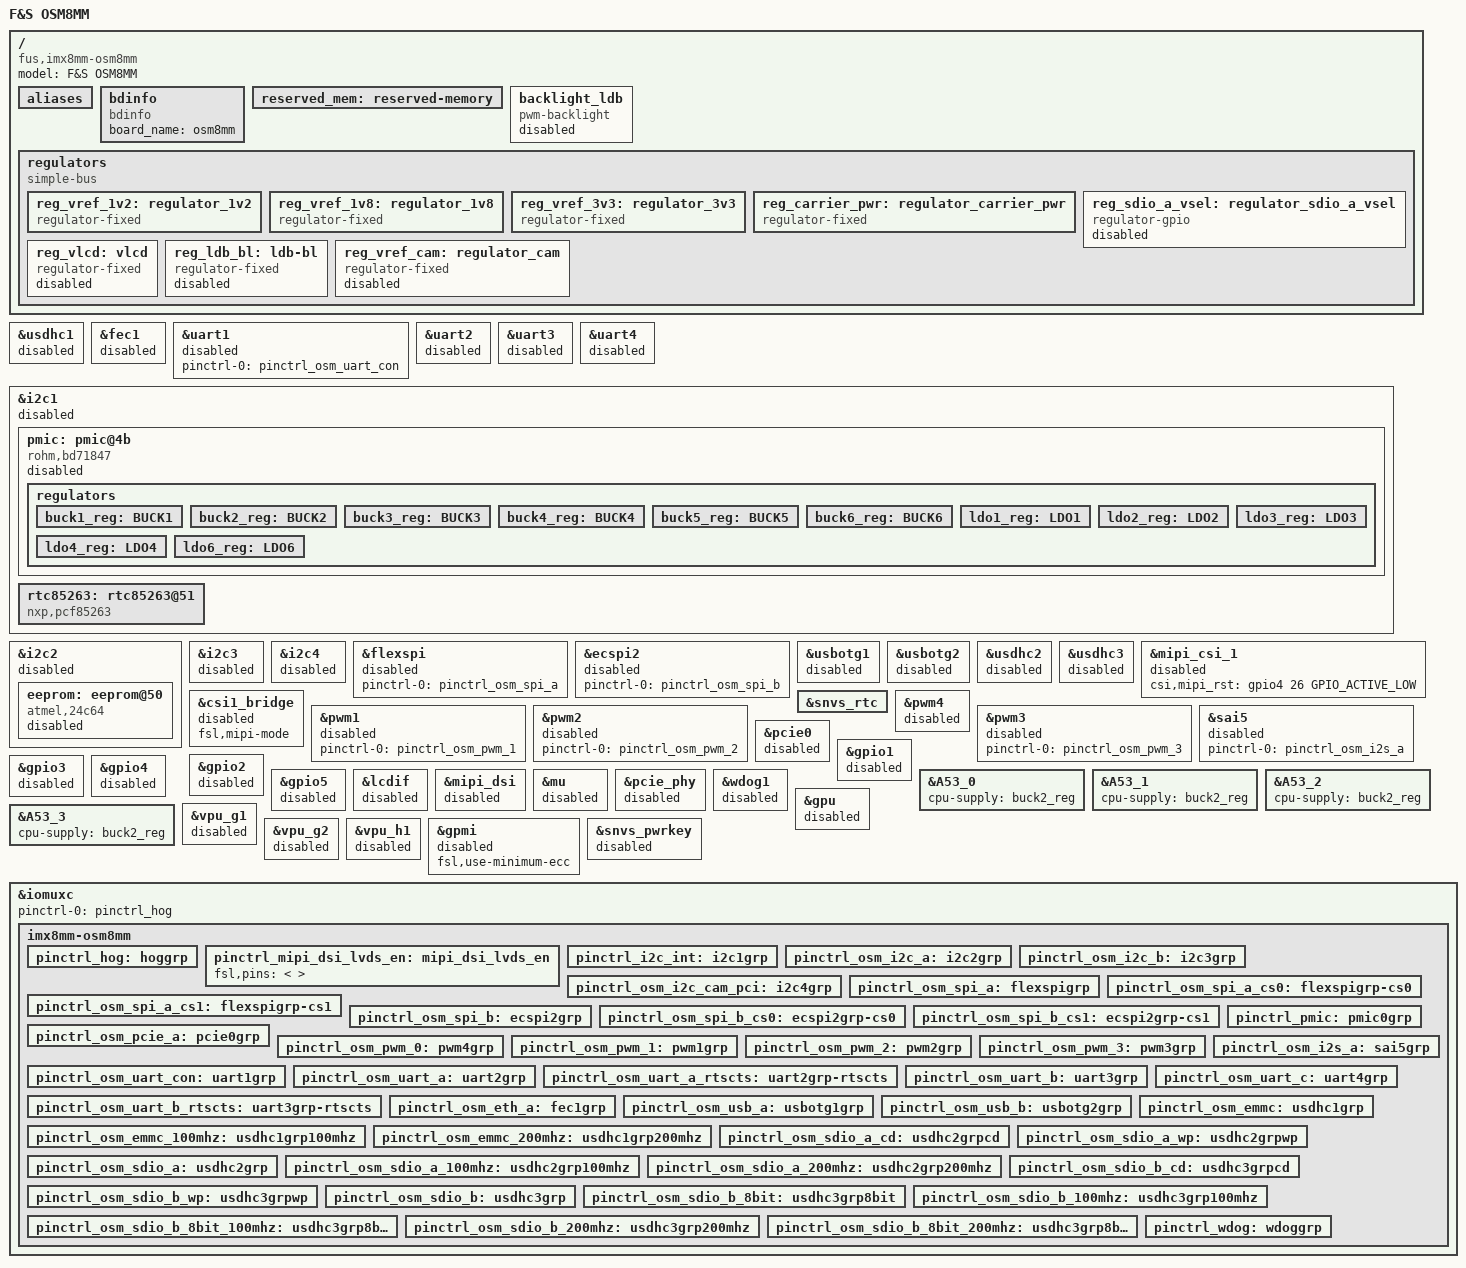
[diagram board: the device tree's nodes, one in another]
/*
 * Copyright (C) 2024 F&S Elektronik Systeme GmbH
 *
 * This program is free software; you can redistribute it and/or modify
 * it under the terms of the GNU General Public License version 2 as
 * published by the Free Software Foundation.
 */

#include <dt-bindings/pwm/pwm.h>
#include <dt-bindings/rtc/nxp,pcf85263.h>
#include <dt-bindings/usb/pd.h>
#include <dt-bindings/phy/phy-imx8-pcie.h>

/* SOC-nodes to OSM-nodes */
osm_emmc: &usdhc1 {};

osm_eth_a: &fec1 {};
osm_uart_con: &uart1 {};
osm_uart_a: &uart2 {};
osm_uart_b: &uart3 {};
osm_uart_c: &uart4 {};
i2c_int: &i2c1 {};
osm_i2c_a: &i2c2 {};
osm_i2c_b: &i2c3 {};
osm_i2c_cam_pci: &i2c4 {};
osm_spi_a: &flexspi {};
osm_spi_b: &ecspi2 {};
osm_usb_a: &usbotg1 {};
osm_usb_b: &usbotg2 {};
osm_sdio_a: &usdhc2 {};
osm_sdio_b: &usdhc3 {};
osm_csi: &mipi_csi_1 {};
osm_csi_bridge: &csi1_bridge {};
rtc_soc: &snvs_rtc {};
osm_pwm_0: &pwm4 {};
osm_pwm_1: &pwm1 {};
osm_pwm_2: &pwm2 {};
osm_pwm_3: &pwm3 {};
osm_i2s_a: &sai5 {};
osm_pcie_a: &pcie0 {};

/ {
	model = "F&S OSM8MM";
	compatible = "fus,imx8mm-osm8mm", "fsl,imx8mm";

	aliases {
		/* Alias for GPMI node. Dont change it
		 * because it used by the bootloader */
		nand = &gpmi;
		emmc = &osm_emmc;

		ethernet0 = &osm_eth_a;
		serial0 = &osm_uart_con;
		serial1 = &osm_uart_a;
		serial2 = &osm_uart_b;
		serial3 = &osm_uart_c;
		i2c0 = &i2c_int;
		i2c1 = &osm_i2c_a;
		i2c2 = &osm_i2c_b;
		i2c3 = &osm_i2c_cam_pci;
		spi0 = &osm_spi_a;
		spi1 = &osm_spi_b;
		usb0 = &osm_usb_a;
		usb1 = &osm_usb_b;
		mmc1 = &osm_sdio_a;
		mmc2 = &osm_sdio_b;
		csi0 = &osm_csi;
		rtc0 = &rtc85263;
		rtc1 = &rtc_soc;
		pwm0 = &osm_pwm_0;
		pwm1 = &osm_pwm_1;
		pwm2 = &osm_pwm_2;
		pwm3 = &osm_pwm_3;
	};

	/* -------------------- BOARD INFO -------------------- */
	bdinfo: bdinfo {
		compatible = "bdinfo";
		board_name = "osm8mm";
	};

	reserved_mem: reserved-memory {
		#address-cells = <2>;
		#size-cells = <2>;
		ranges;
	};

	/* M4/remoteproc reserved-memory + cm4 node live in the board dts,
	 * under its own SUPPORT_M4 guard, not here. */

	backlight_ldb: backlight_ldb {
		compatible = "pwm-backlight";
		#pwm-cells = <3>;
		pwms = <&osm_pwm_0 0 3000000 PWM_POLARITY_INVERTED>;
		power-supply = <&reg_ldb_bl>;
		brightness-levels = <0 1 5 10 18 28 41 56
				     73 92 113 137 163 192 222 255>;
		default-brightness-level = <14>;
		fb-names = "imx-drmdrmfb";
		status = "disabled";
	};

	regulators {
		compatible = "simple-bus";
		#address-cells = <1>;
		#size-cells = <0>;

		/* necessary for lcdif-tc35874-j070wvtc0211 */
		reg_vref_1v2: regulator_1v2 {
			compatible = "regulator-fixed";
			regulator-name = "vref-1V2";
			regulator-min-microvolt = <1200000>;
			regulator-max-microvolt = <1200000>;
			regulator-always-on;
		};

		reg_vref_1v8: regulator_1v8 {
			compatible = "regulator-fixed";
			regulator-name = "vref-1V8";
			regulator-min-microvolt = <1800000>;
			regulator-max-microvolt = <1800000>;
			regulator-always-on;
		};

		reg_vref_3v3: regulator_3v3 {
			compatible = "regulator-fixed";
			regulator-name = "vref-3V3";
			regulator-min-microvolt = <3300000>;
			regulator-max-microvolt = <3300000>;
			regulator-always-on;
		};

		reg_carrier_pwr: regulator_carrier_pwr {
			compatible = "regulator-fixed";
			regulator-name = "CARRIER_PWR";
			gpio = <&gpio4 27 GPIO_ACTIVE_HIGH>;
			regulator-min-microvolt = <3300000>;
			regulator-max-microvolt = <3300000>;
			regulator-boot-on;
			regulator-always-on;
			enable-active-high;
			startup-delay-us = <1000>;
			off-on-delay-us = <12000>;
		};

		/omit-if-no-ref/
		reg_sdio_a_vsel: regulator_sdio_a_vsel {
			compatible = "regulator-gpio";
			regulator-name = "SDIO_A_VSEL";
			gpios = <&gpio1 3 GPIO_ACTIVE_HIGH>;
			regulator-min-microvolt = <1800000>;
			regulator-max-microvolt = <3300000>;
			regulator-type = "voltage";
			regulator-boot-on;
			regulator-always-on;
			enable-active-high;
			states = <1800000 0x1 3300000 0x0>;
			status = "disabled";
		};

		/* LCD power on voltage */
		/omit-if-no-ref/
		reg_vlcd: vlcd {
			compatible = "regulator-fixed";
			regulator-name = "VLCD";
			gpio = <&gpio5 1 GPIO_ACTIVE_HIGH>;
			regulator-min-microvolt = <3300000>;
			regulator-max-microvolt = <3300000>;
			enable-active-high;
			startup-delay-us = <10000>;
			status = "disabled";
		};

		/omit-if-no-ref/
		reg_ldb_bl: ldb-bl {
			compatible = "regulator-fixed";
			regulator-name = "ldb-bl";
			gpio = <&gpio5 0 GPIO_ACTIVE_HIGH>;
			regulator-min-microvolt = <3300000>;
			regulator-max-microvolt = <3300000>;
			enable-active-high;
			status = "disabled";
		};

		/omit-if-no-ref/
		reg_vref_cam: regulator_cam {
			compatible = "regulator-fixed";
			regulator-name = "CAM_ENA";
			gpio = <&gpio4 25 GPIO_ACTIVE_HIGH>;
			regulator-min-microvolt = <1800000>;
			regulator-max-microvolt = <1800000>;
			enable-active-high;
			status = "disabled";
		};
	};

	/* M4/remoteproc rpmsg-audio example intentionally left out - was
	 * already dead (#if 0) in the original file. */
};

/* GPIO declarations */
&gpio1 {
	gpio-line-names =
	/* 0 */   "GPIO_A_0", "GPIO_A_1", "PMIC_WDOG", "SD_A_VSEL",
	/* 4 */   "GPIO_A_2", "GPIO_A_3", "GPIO_A_4", "GPIO_A_5",
	/* 8 */   "GPIO_B_0", "GPIO_B_1", "GPIO_B_2", "GPIO_B_3",
	/* 12 */  "USB_A_EN", "USB_A_OC", "USB_B_EN", "USB_B_OC",
	/* 16 */  "ETH_MDC", "ETH_MDIO", "ETH_A_(S)(R)(G)MII_TXD3", "ETH_A_(S)(R)(G)MII_TXD2",
	/* 20 */  "ETH_A_(S)(R)(G)MII_TXD1", "ETH_A_(S)(R)(G)MII_TXD0", "ETH_A_(R)(G)MII_TX_EN(_ER)", "ETH_A_(R)(G)MII_TX_CLK",
	/* 24 */  "ETH_A_(R)(G)MII_RX_DV(_ER)", "ETH_A_(R)(G)MII_RX_CLK", "ETH_A_(S)(R)(G)MII_RXD0", "ETH_A_(S)(R)(G)MII_RXD1",
	/* 28 */  "ETH_A_(R)(G)MII_RXD2", "ETH_A_(R)(G)MII_RXD3", "", "";
	status = "disabled";
};

&gpio2 {
	gpio-line-names =
	/* 0 */   "SD_eMMC_CLK", "SD_eMMC_CMD", "SD_eMMC_D0", "SD_eMMC_D1",
	/* 4 */   "SD_eMMC_D2", "SD_eMMC_D3", "SD_eMMC_D4", "SD_eMMC_D5",
	/* 8 */   "SD_eMMC_D6", "SD_eMMC_D7", "SD_eMMC_RST", "SD_eMMC_DS",
	/* 12 */  "SDIO_A_CD", "SDIO_A_CLK", "SDIO_A_CMD", "SDIO_A_D0",
	/* 16 */  "SDIO_A_D1", "SDIO_A_D2", "SDIO_A_D3", "SDIO_A_PWR_EN",
	/* 20 */  "SDIO_A_WP", "", "", "",
	/* 24 */  "", "", "", "",
	/* 28 */  "", "", "", "";
	status = "disabled";
};

&gpio3 {
	gpio-line-names =
	/* 0 */   "SPI_A_SCK", "SPI_A_CS0", "SPI_A_CS1", "SDIO_B_D5",
	/* 4 */   "SDIO_B_D6", "SDIO_B_D7", "SPI_A_IO0", "SPI_A_IO1",
	/* 8 */   "SPI_A_IO2", "SPI_A_IO3", "SDIO_B_D0", "SDIO_B_D1",
	/* 12 */  "SDIO_B_D2", "SDIO_B_D3", "", "SDIO_B_D4",
	/* 16 */  "SDIO_B_PWR_EN", "SDIO_B_CLK", "SDIO_B_CMD", "PCIe_PERST",
	/* 20 */  "PCIe_WAKE", "I2S_A_DATA_IN", "I2S_A_LRCLK", "I2S_A_BITCLK",
	/* 24 */  "I2S_A_DATA_OUT", "I2S_MCLK", "", "",
	/* 28 */  "", "", "", "";
	status = "disabled";
};

&gpio4 {
	gpio-line-names =
	/* 0 */   "", "", "", "GPIO_C_3",
	/* 4 */   "GPIO_C_2", "GPIO_C_1", "GPIO_C_0", "GPIO_B_7",
	/* 8 */   "GPIO_B_6", "GPIO_B_5", "", "",
	/* 12 */  "", "", "", "",
	/* 16 */  "", "", "", "",
	/* 20 */  "", "DSI_TE", "SDIO_B_CD", "SDIO_B_WP",
	/* 24 */  "PMIC_IRQ", "CAM_EN", "CAM_RST", "CARRIER_PWR_EN",
	/* 28 */  "PCIe_CLKREQ", "UART_A_RTS", "UART_A_CTS", "PCIe_SM_ALERT";
	status = "disabled";
};

&gpio5 {
	gpio-line-names =
	/* 0 */   "DISP_BL_EN", "DISP_VDD_EN", "DISP_BL_PWM", "PWM_3",
	/* 4 */   "PWM_2", "PWM_1", "SPI_B_CS1", "GPIO_B_4",
	/* 8 */   "UART_B_RTS", "UART_B_CTS", "SPI_B_SCK", "SPI_B_SDO",
	/* 12 */  "SPI_B_SDI", "SPI_B_CS0", "I2C_INT_SCL", "I2C_INT_SDA",
	/* 16 */  "I2C_A_SCL", "I2C_A_SDA", "I2C_B_SCL", "I2C_B_SDA",
	/* 20 */  "I2C_CAM_PCI_SCL", "I2C_CAM_PCI_SDA", "UART_CON_RX", "UART_CON_TX",
	/* 24 */  "UART_A_RX", "UART_A_TX", "UART_B_RX", "UART_B_TX",
	/* 28 */  "UART_C_RX", "UART_C_TX", "", "";
	status = "disabled";
};

/* OSM8MM_I2C_INT */
&i2c_int {
	clock-frequency = <100000>;
	pinctrl-names = "default";
	pinctrl-0 = <&pinctrl_i2c_int>;
	status = "disabled";

	/* PMIC */
	pmic: pmic@4b {
		compatible = "rohm,bd71847";
		reg = <0x4b>;
		pinctrl-names = "default";
		pinctrl-0 = <&pinctrl_pmic>;
		interrupt-parent = <&gpio4>;
		interrupts = <24 GPIO_ACTIVE_LOW>;
		rohm,reset-snvs-powered;

		#clock-cells = <0>;
		clocks = <&osc_32k 0>;
		clock-output-names = "clk-32k-out";
		status = "disabled";

		regulators {
			buck1_reg: BUCK1 {
				regulator-name = "BUCK1";
				regulator-min-microvolt = <700000>;
				regulator-max-microvolt = <1300000>;
				regulator-boot-on;
				regulator-always-on;
				regulator-ramp-delay = <1250>;
				rohm,dvs-run-voltage = <850000>;
				rohm,dvs-suspend-voltage = <750000>;
			};

			buck2_reg: BUCK2 {
				regulator-name = "BUCK2";
				regulator-min-microvolt = <700000>;
				regulator-max-microvolt = <1300000>;
				regulator-boot-on;
				regulator-always-on;
				regulator-ramp-delay = <1250>;
				rohm,dvs-run-voltage = <1000000>;
				rohm,dvs-idle-voltage = <900000>;
                rohm,dvs-suspend-voltage = <0>;
			};

			buck3_reg: BUCK3 {
				// BUCK5 in datasheet
				regulator-name = "BUCK3";
				regulator-min-microvolt = <700000>;
				regulator-max-microvolt = <1350000>;
				regulator-boot-on;
				regulator-always-on;
			};

			buck4_reg: BUCK4 {
				// BUCK6 in datasheet
				regulator-name = "BUCK4";
				regulator-min-microvolt = <3000000>;
				regulator-max-microvolt = <3300000>;
				regulator-boot-on;
				regulator-always-on;
			};

			buck5_reg: BUCK5 {
				// BUCK7 in datasheet
				regulator-name = "BUCK5";
				regulator-min-microvolt = <1605000>;
				regulator-max-microvolt = <1995000>;
				regulator-boot-on;
				regulator-always-on;
			};

			buck6_reg: BUCK6 {
				// BUCK8 in datasheet
				regulator-name = "BUCK6";
				regulator-min-microvolt = <800000>;
				regulator-max-microvolt = <1400000>;
				regulator-boot-on;
				regulator-always-on;
			};

			ldo1_reg: LDO1 {
				regulator-name = "LDO1";
				regulator-min-microvolt = <1600000>;
				regulator-max-microvolt = <1900000>;
				regulator-boot-on;
				regulator-always-on;
			};

			ldo2_reg: LDO2 {
				regulator-name = "LDO2";
				regulator-min-microvolt = <800000>;
				regulator-max-microvolt = <900000>;
				regulator-boot-on;
				regulator-always-on;
			};

			ldo3_reg: LDO3 {
				regulator-name = "LDO3";
				regulator-min-microvolt = <1800000>;
				regulator-max-microvolt = <3300000>;
				regulator-boot-on;
				regulator-always-on;
			};

			ldo4_reg: LDO4 {
				regulator-name = "LDO4";
				regulator-min-microvolt = <900000>;
				regulator-max-microvolt = <1800000>;
				regulator-boot-on;
				regulator-always-on;
			};

			ldo6_reg: LDO6 {
				regulator-name = "LDO6";
				regulator-min-microvolt = <900000>;
				regulator-max-microvolt = <1800000>;
				regulator-boot-on;
				regulator-always-on;
			};
		};
	};

	rtc85263: rtc85263@51 {
		compatible = "nxp,pcf85263";
		reg = <0x51>;
		clock-out = <PCF85263_CLK_OUT_32p768kHz>;

		quartz-load-capacitance = <PCF85263_QUARTZCAP_12p5pF>;
		quartz-drive-strength = <PCF85263_QUARTZDRIVE_LOW>;
	};
};

&osm_i2c_a {
	clock-frequency = <100000>;
	pinctrl-names = "default";
	pinctrl-0 = <&pinctrl_osm_i2c_a>;
	status = "disabled";

	/* EEPROM */
	eeprom: eeprom@50 {
		compatible = "atmel,24c64";
		reg = <0x50>;
		pagesize = <8>;
		vcc-supply = <&reg_vref_1v8>;
		status = "disabled";
	};
};

&osm_i2c_b {
	clock-frequency = <100000>;
	pinctrl-names = "default";
	pinctrl-0 = <&pinctrl_osm_i2c_b>;
	status = "disabled";
};

&osm_i2c_cam_pci {
	clock-frequency = <100000>;
	pinctrl-names = "default";
	pinctrl-0 = <&pinctrl_osm_i2c_cam_pci>;
	status = "disabled";
};

&lcdif {
	status = "disabled";
};

&mipi_dsi {
	status = "disabled";
};

&mu {
	status = "disabled";
};

&osm_pwm_0 {
	pinctrl-names = "default";
	pinctrl-0 = <&pinctrl_osm_pwm_0>;
	#pwm-cells = <3>;
	keep-power;
	status = "disabled";
};

&osm_pwm_1 {
	pinctrl-names = "default";
	pinctrl-0 = <&pinctrl_osm_pwm_1>;
	status = "disabled";
};

&osm_pwm_2 {
	pinctrl-names = "default";
	pinctrl-0 = <&pinctrl_osm_pwm_2>;
	status = "disabled";
};

&osm_pwm_3 {
	pinctrl-names = "default";
	pinctrl-0 = <&pinctrl_osm_pwm_3>;
	status = "disabled";
};

&osm_i2s_a {
	#sound-dai-cells = <0>;
	pinctrl-names = "default";
	pinctrl-0 = <&pinctrl_osm_i2s_a>;
	status = "disabled";
};

/* FSPI not implemented in the NXP FlexSPI driver on this SoC revision - the
 * ADP baseboard overlay deletes this node and replaces it with a
 * spi-gpio bitbang bus instead, see the board dts. */
&osm_spi_a {
	#address-cells = <1>;
	#size-cells = <0>;
	pinctrl-names = "default";
	pinctrl-0 = <&pinctrl_osm_spi_a>;
	status = "disabled";
};

&osm_spi_b {
	#address-cells = <1>;
	#size-cells = <0>;
	pinctrl-names = "default";
	pinctrl-0 = <&pinctrl_osm_spi_b>;
	status = "disabled";
};

&pcie_phy {
	fsl,refclk-pad-mode = <IMX8_PCIE_REFCLK_PAD_OUTPUT>;
	fsl,clkreq-unsupported;
	fsl,tx-deemph-gen1 = <0x2d>;
	fsl,tx-deemph-gen2 = <0xf>;
	status = "disabled";
};

&osm_pcie_a {
	pinctrl-names = "default";
	pinctrl-0 = <&pinctrl_osm_pcie_a>;
	reset-gpio = <&gpio3 19 GPIO_ACTIVE_LOW>;
	/* the wake pin of PCIe must be configured as normal
	 * wakeup source and it is not a specific driver issue
	 */
	//wake-gpio = <&gpio3 20 GPIO_ACTIVE_LOW>;
	assigned-clocks = <&clk IMX8MM_CLK_PCIE1_AUX>,
			  <&clk IMX8MM_CLK_PCIE1_CTRL>;
	assigned-clock-rates = <10000000>, <250000000>;
	assigned-clock-parents = <&clk IMX8MM_SYS_PLL2_50M>,
				 <&clk IMX8MM_SYS_PLL2_250M>;
	ext_osc = <0>;
	l1ss-disabled;
	status = "disabled";
};

&osm_uart_con { /* console */
	pinctrl-names = "default";
	pinctrl-0 = <&pinctrl_osm_uart_con>;
	status = "disabled";
};

&osm_uart_a {
	pinctrl-names = "default";
	pinctrl-0 = <&pinctrl_osm_uart_a>;
	assigned-clocks = <&clk IMX8MM_CLK_UART2>;
	assigned-clock-parents = <&clk IMX8MM_SYS_PLL1_80M>;
	status = "disabled";
};

&osm_uart_b {
	pinctrl-names = "default";
	pinctrl-0 = <&pinctrl_osm_uart_b>;
	assigned-clocks = <&clk IMX8MM_CLK_UART3>;
	assigned-clock-parents = <&clk IMX8MM_SYS_PLL1_80M>;
	status = "disabled";
};

&osm_uart_c {
	pinctrl-names = "default";
	pinctrl-0 = <&pinctrl_osm_uart_c>;
	assigned-clocks = <&clk IMX8MM_CLK_UART4>;
	assigned-clock-parents = <&clk IMX8MM_SYS_PLL1_80M>;
	status = "disabled";
};

&osm_eth_a {
	pinctrl-names = "default";
	pinctrl-0 = <&pinctrl_osm_eth_a>;
	fsl,magic-packet;
	status = "disabled";
};

&osm_usb_a {
	dr_mode = "otg";
	pinctrl-names = "default";
	pinctrl-0 = <&pinctrl_osm_usb_a>;
	picophy,pre-emp-curr-control = <3>;
	picophy,dc-vol-level-adjust = <7>;
	status = "disabled";
};

&osm_usb_b {
	dr_mode = "host";
	pinctrl-names = "default";
	pinctrl-0 = <&pinctrl_osm_usb_b>;
	power-active-high;
	picophy,pre-emp-curr-control = <3>;
	picophy,dc-vol-level-adjust = <7>;
	status = "disabled";
};

&osm_emmc {
	assigned-clocks = <&clk IMX8MM_CLK_USDHC1>;
	assigned-clock-rates = <400000000>;
	pinctrl-names = "default", "state_100mhz", "state_200mhz";
	pinctrl-0 = <&pinctrl_osm_emmc>;
	pinctrl-1 = <&pinctrl_osm_emmc_100mhz>;
	pinctrl-2 = <&pinctrl_osm_emmc_200mhz>;
	bus-width = <8>;
	non-removable;
	status = "disabled";
};

&osm_sdio_a {
	assigned-clocks = <&clk IMX8MM_CLK_USDHC2>;
	assigned-clock-rates = <200000000>;
	bus-width = <4>;
	voltage-ranges = <1800 3300>;
	vqmmc-supply = <&reg_sdio_a_vsel>;
	status = "disabled";
};

&osm_sdio_b {
	assigned-clocks = <&clk IMX8MM_CLK_USDHC3>;
	assigned-clock-rates = <200000000>;
	pinctrl-names = "default", "state_100mhz", "state_200mhz";
	pinctrl-0 = <&pinctrl_osm_sdio_b>;
	pinctrl-1 = <&pinctrl_osm_sdio_b_100mhz>;
	pinctrl-2 = <&pinctrl_osm_sdio_b_200mhz>;
	/* CD/WP/8-bit pinctrl groups and cd-gpios/wp-gpios/bus-width=<8> are
	 * added by the board dts, matching the actually populated pins */
	bus-width = <4>;
	vmmc-supply = <&reg_vref_3v3>;
	vqmmc-supply = <&reg_vref_3v3>;
	pm-ignore-notify;
	keep-power-in-suspend;
	status = "disabled";
};

/* camera-sensor-specific endpoint wiring lives in the board dts, only the
 * fixed CSI-receiver <-> bridge routing + reset line live here */
&osm_csi {
	#address-cells = <1>;
	#size-cells = <0>;
	csi,mipi_rst = <&gpio4 26 GPIO_ACTIVE_LOW>;
	status = "disabled";
};

&osm_csi_bridge {
	fsl,mipi-mode;
	status = "disabled";
};

&wdog1 {
	pinctrl-names = "default";
	pinctrl-0 = <&pinctrl_wdog>;
	fsl,ext-reset-output;
	status = "disabled";
};

&A53_0 {
	cpu-supply = <&buck2_reg>;
};
&A53_1 {
	cpu-supply = <&buck2_reg>;
};

&A53_2 {
	cpu-supply = <&buck2_reg>;
};

&A53_3 {
	cpu-supply = <&buck2_reg>;
};

&gpu {
	status = "disabled";
};

&vpu_g1 {
	status = "disabled";
};

&vpu_g2 {
	status = "disabled";
};

&vpu_h1 {
	status = "disabled";
};

&gpmi {
	fsl,use-minimum-ecc;
	status = "disabled";
};

&snvs_pwrkey {
	status = "disabled";
};

&iomuxc {
	pinctrl-names = "default";
	pinctrl-0 = <&pinctrl_hog>;

	imx8mm-osm8mm {
		/* Pin configs that don't belong anywhere else */
		pinctrl_hog: hoggrp {
			fsl,pins = <
				/* CARRIER_PWR_EN */
				MX8MM_IOMUXC_SAI2_MCLK_GPIO4_IO27	0x00004
				/* SD_A_VSEL */
				MX8MM_IOMUXC_GPIO1_IO03_GPIO1_IO3	0x00004

				/* GPIO_A */
				/* 0 */ MX8MM_IOMUXC_GPIO1_IO00_GPIO1_IO0	0x00004
				/* 1 */ MX8MM_IOMUXC_GPIO1_IO01_GPIO1_IO1	0x00004
				/* 2 */ MX8MM_IOMUXC_GPIO1_IO04_GPIO1_IO4	0x00004
				/* 3 */ MX8MM_IOMUXC_GPIO1_IO05_GPIO1_IO5	0x00004
				/* 4 */ MX8MM_IOMUXC_GPIO1_IO06_GPIO1_IO6	0x00004
				/* 5 */ MX8MM_IOMUXC_GPIO1_IO07_GPIO1_IO7	0x00004
				/* GPIO_B */
				/* 0 */ MX8MM_IOMUXC_GPIO1_IO08_GPIO1_IO8	0x00004
				/* 1 */ MX8MM_IOMUXC_GPIO1_IO09_GPIO1_IO9	0x00004
				/* 2 */ MX8MM_IOMUXC_GPIO1_IO10_GPIO1_IO10	0x00004
				/* 3 */ MX8MM_IOMUXC_GPIO1_IO11_GPIO1_IO11	0x00004
				/* 4 */ MX8MM_IOMUXC_ECSPI1_MOSI_GPIO5_IO7	0x00004
				/* 5 */ MX8MM_IOMUXC_SAI1_RXD7_GPIO4_IO9	0x00004
				/* 6 */ MX8MM_IOMUXC_SAI1_RXD6_GPIO4_IO8	0x00004
				/* 7 */ MX8MM_IOMUXC_SAI1_RXD5_GPIO4_IO7	0x00004

				/* GPIO_C */
				/* 0 */ MX8MM_IOMUXC_SAI1_RXD4_GPIO4_IO6	0x00004
				/* 1 */ MX8MM_IOMUXC_SAI1_RXD3_GPIO4_IO5	0x00004
				/* 2 */ MX8MM_IOMUXC_SAI1_RXD2_GPIO4_IO4	0x00004
				/* 3 */ MX8MM_IOMUXC_SAI1_RXD1_GPIO4_IO3	0x00004
				/* 4 */ /* VDD_EN: Disable display for usage */
				/* 4 */ MX8MM_IOMUXC_SAI3_TXD_GPIO5_IO1		0x00004
				/* 5 */ /* BL_EN: Disable backlight control for usage */
				/* 5 */ MX8MM_IOMUXC_SAI3_TXC_GPIO5_IO0		0x00004
				/* 6 */ /* CAM_EN: Disable CAM for usage */
				/* 6 */ MX8MM_IOMUXC_SAI2_TXC_GPIO4_IO25	0x00004
				/* 7 */ /* CAM_RST: Disable CAM for usage */
				/* 7 */ MX8MM_IOMUXC_SAI2_TXD0_GPIO4_IO26	0x00004
			>;
		};

		pinctrl_mipi_dsi_lvds_en: mipi_dsi_lvds_en {
			fsl,pins = <
			>;
		};

		pinctrl_i2c_int: i2c1grp {
			fsl,pins = <
				MX8MM_IOMUXC_I2C1_SCL_I2C1_SCL		0x40000083
				MX8MM_IOMUXC_I2C1_SDA_I2C1_SDA		0x40000083
			>;
		};

		pinctrl_osm_i2c_a: i2c2grp {
			fsl,pins = <
				MX8MM_IOMUXC_I2C2_SCL_I2C2_SCL		0x40000083
				MX8MM_IOMUXC_I2C2_SDA_I2C2_SDA		0x40000083
			>;
		};

		pinctrl_osm_i2c_b: i2c3grp {
			fsl,pins = <
				MX8MM_IOMUXC_I2C3_SCL_I2C3_SCL		0x40000083
				MX8MM_IOMUXC_I2C3_SDA_I2C3_SDA		0x40000083
			>;
		};

		pinctrl_osm_i2c_cam_pci: i2c4grp {
			fsl,pins = <
				MX8MM_IOMUXC_I2C4_SCL_I2C4_SCL		0x40000083
				MX8MM_IOMUXC_I2C4_SDA_I2C4_SDA		0x40000083
			>;
		};

		pinctrl_osm_spi_a: flexspigrp {
			fsl,pins = <
				MX8MM_IOMUXC_NAND_ALE_QSPI_A_SCLK		0x00082
				MX8MM_IOMUXC_NAND_DATA00_QSPI_A_DATA0	0x00082
				MX8MM_IOMUXC_NAND_DATA01_QSPI_A_DATA1	0x00082
				MX8MM_IOMUXC_NAND_DATA02_QSPI_A_DATA2	0x00082
				MX8MM_IOMUXC_NAND_DATA03_QSPI_A_DATA3	0x00082
			>;
		};

		pinctrl_osm_spi_a_cs0: flexspigrp-cs0 {
			fsl,pins = <
				MX8MM_IOMUXC_NAND_CE0_B_QSPI_A_SS0_B	0x40000
			>;
		};

		pinctrl_osm_spi_a_cs1: flexspigrp-cs1 {
			fsl,pins = <
				MX8MM_IOMUXC_NAND_CE1_B_QSPI_A_SS1_B	0x40000
			>;
		};

		pinctrl_osm_spi_b: ecspi2grp {
			fsl,pins = <
				MX8MM_IOMUXC_ECSPI2_SCLK_ECSPI2_SCLK	0x00082
				MX8MM_IOMUXC_ECSPI2_MOSI_ECSPI2_MOSI	0x00082
				MX8MM_IOMUXC_ECSPI2_MISO_ECSPI2_MISO	0x00082
			>;
		};

		pinctrl_osm_spi_b_cs0: ecspi2grp-cs0 {
			fsl,pins = <
				MX8MM_IOMUXC_ECSPI2_SS0_GPIO5_IO13		0x00004
			>;
		};

		pinctrl_osm_spi_b_cs1: ecspi2grp-cs1 {
			fsl,pins = <
				MX8MM_IOMUXC_ECSPI1_SCLK_GPIO5_IO6		0x00004
			>;
		};

		pinctrl_osm_pcie_a: pcie0grp {
			fsl,pins = <
				/* mPCIE_PERST */
				MX8MM_IOMUXC_SAI5_RXFS_GPIO3_IO19	0x00001
				/* mPCIE_WAKE */
				MX8MM_IOMUXC_SAI5_RXC_GPIO3_IO20	0x00004
			>;
		};

		pinctrl_pmic: pmic0grp {
			fsl,pins = <
				/* IRQn */
				MX8MM_IOMUXC_SAI2_TXFS_GPIO4_IO24	0x00001
			>;
		};

		pinctrl_osm_pwm_0: pwm4grp {
			fsl,pins = <
				MX8MM_IOMUXC_SAI3_MCLK_PWM4_OUT		0x00004
			>;
		};

		pinctrl_osm_pwm_1: pwm1grp {
			fsl,pins = <
				MX8MM_IOMUXC_SPDIF_EXT_CLK_PWM1_OUT	0x00004
			>;
		};

		pinctrl_osm_pwm_2: pwm2grp {
			fsl,pins = <
				MX8MM_IOMUXC_SPDIF_RX_PWM2_OUT	0x00004
			>;
		};

		pinctrl_osm_pwm_3: pwm3grp {
			fsl,pins = <
				MX8MM_IOMUXC_SPDIF_TX_PWM3_OUT	0x00004
			>;
		};

		pinctrl_osm_i2s_a: sai5grp {
			fsl,pins = <
				MX8MM_IOMUXC_SAI5_MCLK_SAI5_MCLK	0x000d6
				MX8MM_IOMUXC_SAI5_RXD1_SAI5_TX_SYNC	0x000d6
				MX8MM_IOMUXC_SAI5_RXD2_SAI5_TX_BCLK	0x000d6
				MX8MM_IOMUXC_SAI5_RXD3_SAI5_TX_DATA0	0x000d6
				MX8MM_IOMUXC_SAI5_RXD0_SAI5_RX_DATA0	0x000d6
			>;
		};

		/* debug output */
		pinctrl_osm_uart_con: uart1grp {
			fsl,pins = <
				MX8MM_IOMUXC_UART1_RXD_UART1_DCE_RX	0x00000
				MX8MM_IOMUXC_UART1_TXD_UART1_DCE_TX	0x00000
			>;
		};

		pinctrl_osm_uart_a: uart2grp {
			fsl,pins = <
				MX8MM_IOMUXC_UART2_RXD_UART2_DCE_RX	0x00000
				MX8MM_IOMUXC_UART2_TXD_UART2_DCE_TX	0x00000
			>;
		};

		pinctrl_osm_uart_a_rtscts: uart2grp-rtscts {
			fsl,pins = <
				/* CTS */
				MX8MM_IOMUXC_SAI3_RXC_UART2_DCE_CTS_B	0x00000
				/* RTS */
				MX8MM_IOMUXC_SAI3_RXD_UART2_DCE_RTS_B	0x00000
			>;
		};

		pinctrl_osm_uart_b: uart3grp {
			fsl,pins = <
				MX8MM_IOMUXC_UART3_RXD_UART3_DCE_RX	0x00000
				MX8MM_IOMUXC_UART3_TXD_UART3_DCE_TX	0x00000
			>;
		};

		pinctrl_osm_uart_b_rtscts: uart3grp-rtscts {
			fsl,pins = <
				/* CTS */
				MX8MM_IOMUXC_ECSPI1_MISO_UART3_DCE_CTS_B	0x00000
				/* RTS */
				MX8MM_IOMUXC_ECSPI1_SS0_UART3_DCE_RTS_B		0x00000
			>;
		};

		pinctrl_osm_uart_c: uart4grp {
			fsl,pins = <
				MX8MM_IOMUXC_UART4_RXD_UART4_DCE_RX	0x00000
				MX8MM_IOMUXC_UART4_TXD_UART4_DCE_TX	0x00000
			>;
		};

		pinctrl_osm_eth_a: fec1grp {
			fsl,pins = <
				MX8MM_IOMUXC_ENET_MDC_ENET1_MDC		0x00003
				MX8MM_IOMUXC_ENET_MDIO_ENET1_MDIO	0x00003
				MX8MM_IOMUXC_ENET_TD3_ENET1_RGMII_TD3	0x0001f
				MX8MM_IOMUXC_ENET_TD2_ENET1_RGMII_TD2	0x0001f
				MX8MM_IOMUXC_ENET_TD1_ENET1_RGMII_TD1	0x0001f
				MX8MM_IOMUXC_ENET_TD0_ENET1_RGMII_TD0	0x0001f
				MX8MM_IOMUXC_ENET_RD3_ENET1_RGMII_RD3	0x00091
				MX8MM_IOMUXC_ENET_RD2_ENET1_RGMII_RD2	0x00091
				MX8MM_IOMUXC_ENET_RD1_ENET1_RGMII_RD1	0x00091
				MX8MM_IOMUXC_ENET_RD0_ENET1_RGMII_RD0	0x00091
				MX8MM_IOMUXC_ENET_TXC_ENET1_RGMII_TXC	0x0001f
				MX8MM_IOMUXC_ENET_RXC_ENET1_RGMII_RXC	0x00091
				MX8MM_IOMUXC_ENET_RX_CTL_ENET1_RGMII_RX_CTL	0x00091
				MX8MM_IOMUXC_ENET_TX_CTL_ENET1_RGMII_TX_CTL	0x0001f
			>;
		};

		pinctrl_osm_usb_a: usbotg1grp {
			fsl,pins = <
				MX8MM_IOMUXC_GPIO1_IO12_USB1_OTG_PWR	0x00004
				MX8MM_IOMUXC_GPIO1_IO13_USB1_OTG_OC		0x00004
			>;
		};

		pinctrl_osm_usb_b: usbotg2grp {
			fsl,pins = <
				MX8MM_IOMUXC_GPIO1_IO14_USB2_OTG_PWR	0x00004
				MX8MM_IOMUXC_GPIO1_IO15_USB2_OTG_OC		0x00004
			>;
		};

		pinctrl_osm_emmc: usdhc1grp {
			fsl,pins = <
				MX8MM_IOMUXC_SD1_CLK_USDHC1_CLK		0x00190
				MX8MM_IOMUXC_SD1_CMD_USDHC1_CMD		0x00090
				MX8MM_IOMUXC_SD1_DATA0_USDHC1_DATA0	0x00090
				MX8MM_IOMUXC_SD1_DATA1_USDHC1_DATA1	0x001d0
				MX8MM_IOMUXC_SD1_DATA2_USDHC1_DATA2	0x001d0
				MX8MM_IOMUXC_SD1_DATA3_USDHC1_DATA3	0x001d0
				MX8MM_IOMUXC_SD1_DATA4_USDHC1_DATA4	0x001d0
				MX8MM_IOMUXC_SD1_DATA5_USDHC1_DATA5	0x001d0
				MX8MM_IOMUXC_SD1_DATA6_USDHC1_DATA6	0x001d0
				MX8MM_IOMUXC_SD1_DATA7_USDHC1_DATA7	0x001d0
				MX8MM_IOMUXC_SD1_STROBE_USDHC1_STROBE	0x00190
				MX8MM_IOMUXC_SD1_RESET_B_USDHC1_RESET_B	0x00004
			>;
		};

		pinctrl_osm_emmc_100mhz: usdhc1grp100mhz {
			fsl,pins = <
				MX8MM_IOMUXC_SD1_CLK_USDHC1_CLK		0x00194
				MX8MM_IOMUXC_SD1_CMD_USDHC1_CMD		0x00094
				MX8MM_IOMUXC_SD1_DATA0_USDHC1_DATA0	0x00094
				MX8MM_IOMUXC_SD1_DATA1_USDHC1_DATA1	0x001d4
				MX8MM_IOMUXC_SD1_DATA2_USDHC1_DATA2	0x001d4
				MX8MM_IOMUXC_SD1_DATA3_USDHC1_DATA3	0x001d4
				MX8MM_IOMUXC_SD1_DATA4_USDHC1_DATA4	0x001d4
				MX8MM_IOMUXC_SD1_DATA5_USDHC1_DATA5	0x001d4
				MX8MM_IOMUXC_SD1_DATA6_USDHC1_DATA6	0x001d4
				MX8MM_IOMUXC_SD1_DATA7_USDHC1_DATA7	0x001d4
				MX8MM_IOMUXC_SD1_STROBE_USDHC1_STROBE	0x00194
				MX8MM_IOMUXC_SD1_RESET_B_USDHC1_RESET_B	0x00004
			>;
		};

		pinctrl_osm_emmc_200mhz: usdhc1grp200mhz {
			fsl,pins = <
				MX8MM_IOMUXC_SD1_CLK_USDHC1_CLK		0x00196
				MX8MM_IOMUXC_SD1_CMD_USDHC1_CMD		0x00096
				MX8MM_IOMUXC_SD1_DATA0_USDHC1_DATA0	0x00096
				MX8MM_IOMUXC_SD1_DATA1_USDHC1_DATA1	0x001d6
				MX8MM_IOMUXC_SD1_DATA2_USDHC1_DATA2	0x001d6
				MX8MM_IOMUXC_SD1_DATA3_USDHC1_DATA3	0x001d6
				MX8MM_IOMUXC_SD1_DATA4_USDHC1_DATA4	0x001d6
				MX8MM_IOMUXC_SD1_DATA5_USDHC1_DATA5	0x001d6
				MX8MM_IOMUXC_SD1_DATA6_USDHC1_DATA6	0x001d6
				MX8MM_IOMUXC_SD1_DATA7_USDHC1_DATA7	0x001d6
				MX8MM_IOMUXC_SD1_STROBE_USDHC1_STROBE	0x00196
				MX8MM_IOMUXC_SD1_RESET_B_USDHC1_RESET_B	0x00004
			>;
		};

		pinctrl_osm_sdio_a_cd: usdhc2grpcd {
			fsl,pins = <
				/* CD */
				MX8MM_IOMUXC_SD2_CD_B_GPIO2_IO12	0x00084
			>;
		};

		pinctrl_osm_sdio_a_wp: usdhc2grpwp {
			fsl,pins = <
				/* WP */
				MX8MM_IOMUXC_SD2_WP_USDHC2_WP		0x00084
			>;
		};

		pinctrl_osm_sdio_a: usdhc2grp {
			fsl,pins = <
				MX8MM_IOMUXC_SD2_CLK_USDHC2_CLK		0x00190
				MX8MM_IOMUXC_SD2_CMD_USDHC2_CMD		0x000d0
				MX8MM_IOMUXC_SD2_DATA0_USDHC2_DATA0	0x000d0
				MX8MM_IOMUXC_SD2_DATA1_USDHC2_DATA1	0x001d0
				MX8MM_IOMUXC_SD2_DATA2_USDHC2_DATA2	0x001d0
				MX8MM_IOMUXC_SD2_DATA3_USDHC2_DATA3	0x001d0
			>;
		};

		pinctrl_osm_sdio_a_100mhz: usdhc2grp100mhz {
			fsl,pins = <
				MX8MM_IOMUXC_SD2_CLK_USDHC2_CLK		0x00194
				MX8MM_IOMUXC_SD2_CMD_USDHC2_CMD		0x000d4
				MX8MM_IOMUXC_SD2_DATA0_USDHC2_DATA0	0x000d4
				MX8MM_IOMUXC_SD2_DATA1_USDHC2_DATA1	0x001d4
				MX8MM_IOMUXC_SD2_DATA2_USDHC2_DATA2	0x001d4
				MX8MM_IOMUXC_SD2_DATA3_USDHC2_DATA3	0x001d4
			>;
		};

		pinctrl_osm_sdio_a_200mhz: usdhc2grp200mhz {
			fsl,pins = <
				MX8MM_IOMUXC_SD2_CLK_USDHC2_CLK		0x00196
				MX8MM_IOMUXC_SD2_CMD_USDHC2_CMD		0x000d6
				MX8MM_IOMUXC_SD2_DATA0_USDHC2_DATA0	0x000d6
				MX8MM_IOMUXC_SD2_DATA1_USDHC2_DATA1	0x001d6
				MX8MM_IOMUXC_SD2_DATA2_USDHC2_DATA2	0x001d6
				MX8MM_IOMUXC_SD2_DATA3_USDHC2_DATA3	0x001d6
			>;
		};

		pinctrl_osm_sdio_b_cd: usdhc3grpcd {
			fsl,pins = <
				/* CD */
				MX8MM_IOMUXC_SAI2_RXC_GPIO4_IO22	0x00084
			>;
		};

		pinctrl_osm_sdio_b_wp: usdhc3grpwp {
			fsl,pins = <
				/* WP */
				MX8MM_IOMUXC_SAI2_RXD0_GPIO4_IO23	0x00084
			>;
		};

		pinctrl_osm_sdio_b: usdhc3grp {
			fsl,pins = <
				MX8MM_IOMUXC_NAND_WE_B_USDHC3_CLK	0x00190
				MX8MM_IOMUXC_NAND_WP_B_USDHC3_CMD	0x000d0
				MX8MM_IOMUXC_NAND_DATA04_USDHC3_DATA0	0x000d0
				MX8MM_IOMUXC_NAND_DATA05_USDHC3_DATA1	0x001d0
				MX8MM_IOMUXC_NAND_DATA06_USDHC3_DATA2	0x001d0
				MX8MM_IOMUXC_NAND_DATA07_USDHC3_DATA3	0x001d0
				MX8MM_IOMUXC_NAND_READY_B_SD3_RESET_B	0x00004
			>;
		};

		pinctrl_osm_sdio_b_8bit: usdhc3grp8bit {
			fsl,pins = <
				MX8MM_IOMUXC_NAND_RE_B_USDHC3_DATA4	0x001d0
				MX8MM_IOMUXC_NAND_CE2_B_USDHC3_DATA5	0x001d0
				MX8MM_IOMUXC_NAND_CE3_B_USDHC3_DATA6	0x001d0
				MX8MM_IOMUXC_NAND_CLE_USDHC3_DATA7	0x001d0
			>;
		};

		pinctrl_osm_sdio_b_100mhz: usdhc3grp100mhz {
			fsl,pins = <
				MX8MM_IOMUXC_NAND_WE_B_USDHC3_CLK	0x00194
				MX8MM_IOMUXC_NAND_WP_B_USDHC3_CMD	0x000d4
				MX8MM_IOMUXC_NAND_DATA04_USDHC3_DATA0	0x000d4
				MX8MM_IOMUXC_NAND_DATA05_USDHC3_DATA1	0x001d4
				MX8MM_IOMUXC_NAND_DATA06_USDHC3_DATA2	0x001d4
				MX8MM_IOMUXC_NAND_DATA07_USDHC3_DATA3	0x001d4
				MX8MM_IOMUXC_NAND_READY_B_SD3_RESET_B	0x00004
			>;
		};

		pinctrl_osm_sdio_b_8bit_100mhz: usdhc3grp8bit100mhz {
			fsl,pins = <
				MX8MM_IOMUXC_NAND_RE_B_USDHC3_DATA4	0x001d4
				MX8MM_IOMUXC_NAND_CE2_B_USDHC3_DATA5	0x001d4
				MX8MM_IOMUXC_NAND_CE3_B_USDHC3_DATA6	0x001d4
				MX8MM_IOMUXC_NAND_CLE_USDHC3_DATA7	0x001d4
			>;
		};

		pinctrl_osm_sdio_b_200mhz: usdhc3grp200mhz {
			fsl,pins = <
				MX8MM_IOMUXC_NAND_WE_B_USDHC3_CLK	0x00196
				MX8MM_IOMUXC_NAND_WP_B_USDHC3_CMD	0x000d6
				MX8MM_IOMUXC_NAND_DATA04_USDHC3_DATA0	0x000d6
				MX8MM_IOMUXC_NAND_DATA05_USDHC3_DATA1	0x001d6
				MX8MM_IOMUXC_NAND_DATA06_USDHC3_DATA2	0x001d6
				MX8MM_IOMUXC_NAND_DATA07_USDHC3_DATA3	0x001d6
				MX8MM_IOMUXC_NAND_READY_B_SD3_RESET_B	0x00004
			>;
		};

		pinctrl_osm_sdio_b_8bit_200mhz: usdhc3grp8bit200mhz {
			fsl,pins = <
				MX8MM_IOMUXC_NAND_RE_B_USDHC3_DATA4	0x001d6
				MX8MM_IOMUXC_NAND_CE2_B_USDHC3_DATA5	0x001d6
				MX8MM_IOMUXC_NAND_CE3_B_USDHC3_DATA6	0x001d6
				MX8MM_IOMUXC_NAND_CLE_USDHC3_DATA7	0x001d6
			>;
		};

		pinctrl_wdog: wdoggrp {
			fsl,pins = <
				MX8MM_IOMUXC_GPIO1_IO02_WDOG1_WDOG_B	0x000a6
			>;
		};
	};
};
